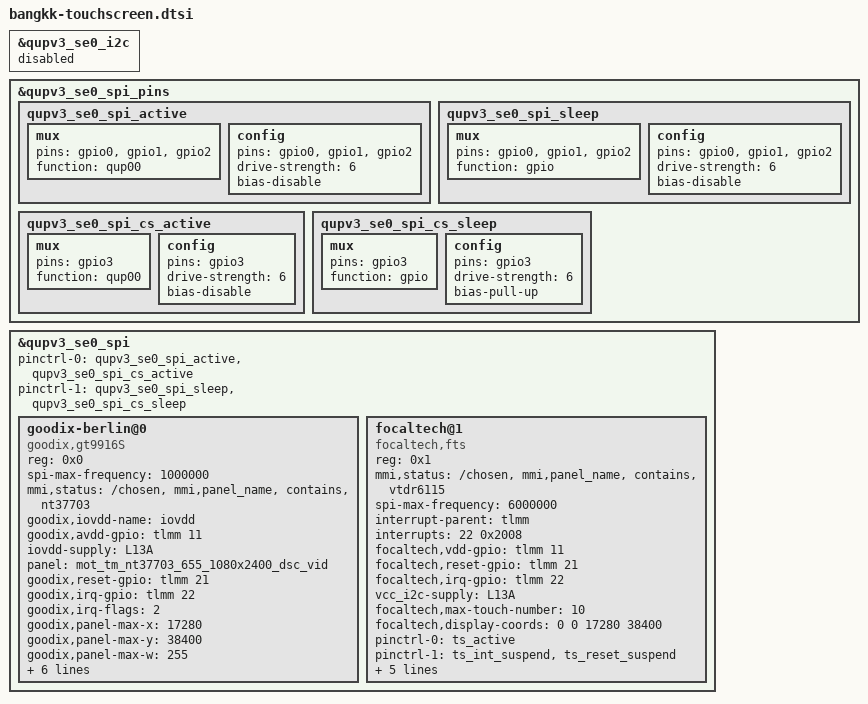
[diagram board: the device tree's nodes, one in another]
/*
 * Copyright (c) 2019, The Linux Foundation. All rights reserved.
 *
 * This program is free software; you can redistribute it and/or modify
 * it under the terms of the GNU General Public License version 2 and
 * only version 2 as published by the Free Software Foundation.
 *
 * This program is distributed in the hope that it will be useful,
 * but WITHOUT ANY WARRANTY; without even the implied warranty of
 * MERCHANTABILITY or FITNESS FOR A PARTICULAR PURPOSE.  See the
 * GNU General Public License for more details.
 */

&qupv3_se0_i2c {
	status = "disabled";
};

&qupv3_se0_spi_pins {
	qupv3_se0_spi_active: qupv3_se0_spi_active {
		mux {
			pins = "gpio0", "gpio1", "gpio2";
			function = "qup00";
		};

		config {
			pins = "gpio0", "gpio1", "gpio2";
			drive-strength = <6>;
			bias-disable;
		};
	};

	qupv3_se0_spi_sleep: qupv3_se0_spi_sleep {
		mux {
			pins = "gpio0", "gpio1", "gpio2";
			function = "gpio";
		};

		config {
			pins = "gpio0", "gpio1", "gpio2";
			drive-strength = <6>;
			bias-disable;
		};
	};

	qupv3_se0_spi_cs_active: qupv3_se0_spi_cs_active {
		mux {
			pins = "gpio3";
			function = "qup00";
		};

		config {
			pins = "gpio3";
			drive-strength = <6>;
			bias-disable;
		};
	};

	qupv3_se0_spi_cs_sleep: qupv3_se0_spi_cs_sleep {
		mux {
			pins = "gpio3";
			function = "gpio";
		};

		config {
			pins = "gpio3";
			drive-strength = <6>;
			bias-pull-up;
		};
	};
};

&qupv3_se0_spi {
	status = "ok";

	pinctrl-0 = <&qupv3_se0_spi_active &qupv3_se0_spi_cs_active>;
	pinctrl-1 = <&qupv3_se0_spi_sleep &qupv3_se0_spi_cs_sleep>;

	goodix-berlin@0 {
		compatible = "goodix,gt9916S";
		reg = <0x0>;
		spi-max-frequency = <1000000>;

		mmi,status = "/chosen","mmi,panel_name","contains","nt37703";
		//goodix,avdd-name = "avdd";
		goodix,iovdd-name = "iovdd";
		goodix,avdd-gpio = <&tlmm 11 0x0>;
		iovdd-supply = <&L13A>;

		panel = <&mot_tm_nt37703_655_1080x2400_dsc_vid>;

		goodix,reset-gpio = <&tlmm 21 0x0>;
		goodix,irq-gpio = <&tlmm 22 0x0>;
		goodix,irq-flags = <2>;
		goodix,panel-max-x = <17280>;
		goodix,panel-max-y = <38400>;
		goodix,panel-max-w = <255>;

		goodix,panel-max-p = <4096>;
		goodix,firmware-name = "goodix_firmware.bin";
		goodix,config-name = "goodix_cfg_group.bin";
		mmi,usb-charger-detection;
		mmi,enable-gestures;
		mmi,supported_gesture_type = <0x07>;
		status = "ok";
	};

	focaltech@1{
		compatible = "focaltech,fts";
		reg = <0x1>;
		//mmi,status = "/chosen","vtdr6115";
		mmi,status = "/chosen","mmi,panel_name","contains","vtdr6115";
		spi-max-frequency = <6000000>;
		interrupt-parent = <&tlmm>;
		interrupts = <22 0x2008>;
		focaltech,vdd-gpio = <&tlmm 11 0x00>;
		focaltech,reset-gpio = <&tlmm 21 0x00>;
		focaltech,irq-gpio = <&tlmm 22 0x02008>;
		vcc_i2c-supply = <&L13A>;
		focaltech,max-touch-number = <10>;
		focaltech,display-coords =  <0 0 17280 38400>;

		pinctrl-names = "pmx_ts_active","pmx_ts_suspend",
						"pmx_ts_release";
		pinctrl-0 = <&ts_active>;
		pinctrl-1 = <&ts_int_suspend &ts_reset_suspend>;
		pinctrl-2 = <&pmx_ts_release>;

		panel = <&mot_csot_vtdr6115_655_1080x2400_dsc_vid>;
		mmi,usb-charger-detection;
		mmi,enable-gestures;
		mmi,supported_gesture_type = <0x07>;
		status = "ok";
 	};
};
